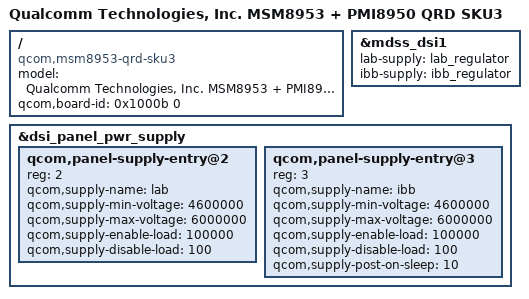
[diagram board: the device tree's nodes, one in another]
/dts-v1/;

#include "msm8953.dtsi"
#include "pmi8950.dtsi"
#include "msm8953-pmi8950.dtsi"
#include "msm8953-qrd-sku3.dtsi"
#include "msm8953-mdss-panels.dtsi"
#include "msm8953-camera-sensor-qrd.dtsi"

/ {
	model = "Qualcomm Technologies, Inc. MSM8953 + PMI8950 QRD SKU3";
	compatible = "qcom,msm8953-qrd-sku3",
		   "qcom,msm8953-qrd", "qcom,msm8953", "qcom,qrd", "xiaomi,tiffany";
	qcom,board-id= <0x1000b 0>;
};

&mdss_dsi1 {
	lab-supply = <&lab_regulator>;
	ibb-supply = <&ibb_regulator>;
};

&dsi_panel_pwr_supply {
	qcom,panel-supply-entry@2 {
		reg = <2>;
		qcom,supply-name = "lab";
		qcom,supply-min-voltage = <4600000>;
		qcom,supply-max-voltage = <6000000>;
		qcom,supply-enable-load = <100000>;
		qcom,supply-disable-load = <100>;
	};

	qcom,panel-supply-entry@3 {
		reg = <3>;
		qcom,supply-name = "ibb";
		qcom,supply-min-voltage = <4600000>;
		qcom,supply-max-voltage = <6000000>;
		qcom,supply-enable-load = <100000>;
		qcom,supply-disable-load = <100>;
		qcom,supply-post-on-sleep = <10>;
	};
};
#include "mi8953/common/common.dtsi"
#include "mi8953/tiffany/tiffany.dtsi"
